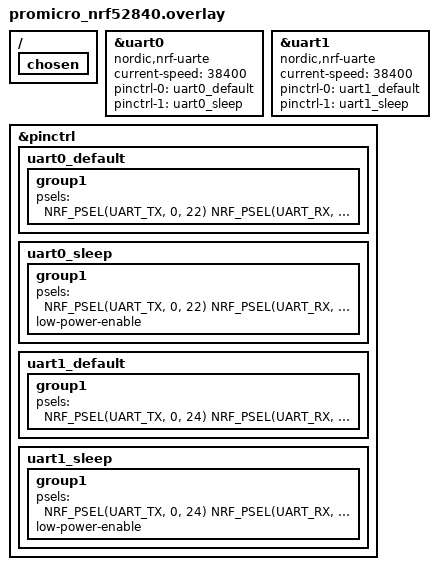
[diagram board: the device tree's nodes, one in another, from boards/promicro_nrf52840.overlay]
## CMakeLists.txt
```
cmake_minimum_required(VERSION 3.20.0)

find_package(Zephyr REQUIRED HINTS $ENV{ZEPHYR_BASE})

project(double_uart_viewer)

target_sources(app PRIVATE src/main.c)
```

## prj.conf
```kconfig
CONFIG_LOG=y
CONFIG_LOG_MODE_IMMEDIATE=y
CONFIG_LOG_BACKEND_UART=n
CONFIG_LOG_BACKEND_RTT=y
CONFIG_USE_SEGGER_RTT=y
CONFIG_RTT_CONSOLE=y
CONFIG_LOG_DEFAULT_LEVEL=4
CONFIG_BUILD_OUTPUT_UF2=y
```

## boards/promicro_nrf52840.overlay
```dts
/ {
    chosen {
    };
};

&uart0 {
    compatible = "nordic,nrf-uarte";
    status = "okay";
    current-speed = <38400>;
    pinctrl-0 = <&uart0_default>;
    pinctrl-1 = <&uart0_sleep>;
    pinctrl-names = "default", "sleep";
};

&uart1 {
    compatible = "nordic,nrf-uarte";
    status = "okay";
    current-speed = <38400>;
    pinctrl-0 = <&uart1_default>;
    pinctrl-1 = <&uart1_sleep>;
    pinctrl-names = "default", "sleep";
};

&pinctrl {
    uart0_default: uart0_default {
        group1 {
            psels = <NRF_PSEL(UART_TX, 0, 22)
                     NRF_PSEL(UART_RX, 0, 20)>;
        };
    };
    uart0_sleep: uart0_sleep {
        group1 {
            psels = <NRF_PSEL(UART_TX, 0, 22)
                     NRF_PSEL(UART_RX, 0, 20)>;
            low-power-enable;
        };
    };
    uart1_default: uart1_default {
        group1 {
            psels = <NRF_PSEL(UART_TX, 0, 24)
                     NRF_PSEL(UART_RX, 1, 0)>;
        };
    };
    uart1_sleep: uart1_sleep {
        group1 {
            psels = <NRF_PSEL(UART_TX, 0, 24)
                     NRF_PSEL(UART_RX, 1, 0)>;
            low-power-enable;
        };
    };
};
```

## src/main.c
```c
#include <zephyr/kernel.h>
#include <zephyr/device.h>
#include <zephyr/drivers/uart.h>
#include <zephyr/drivers/gpio.h>
#include <zephyr/logging/log.h>

LOG_MODULE_REGISTER(main, LOG_LEVEL_DBG);

/* ── UART devices ───────────────────────────────────────────── */
static const struct device *uart0_dev = DEVICE_DT_GET(DT_NODELABEL(uart0));
static const struct device *uart1_dev = DEVICE_DT_GET(DT_NODELABEL(uart1));

/* ── GPIO P0.13 ─────────────────────────────────────────────── */
static const struct device *gpio0_dev = DEVICE_DT_GET(DT_NODELABEL(gpio0));

/* ── Line buffers ───────────────────────────────────────────── */
static char line0[256];
static char line1[256];
static int  idx0;
static int  idx1;

/* ── UART0 callback ─────────────────────────────────────────── */
static void uart0_cb(const struct device *dev, void *user_data)
{
    if (!uart_irq_update(dev) || !uart_irq_rx_ready(dev)) {
        return;
    }

    uint8_t buf[64];
    int len;

    while ((len = uart_fifo_read(dev, buf, sizeof(buf))) > 0) {
        for (int i = 0; i < len; i++) {
            char c = buf[i];
            if (c == '\n' || idx0 >= sizeof(line0) - 1) {
                line0[idx0] = '\0';
                LOG_INF("[UART0] %s", line0);
                idx0 = 0;
            } else if (c != '\r') {
                line0[idx0++] = c;
            }
        }
    }
}

/* ── UART1 callback ─────────────────────────────────────────── */
static void uart1_cb(const struct device *dev, void *user_data)
{
    if (!uart_irq_update(dev) || !uart_irq_rx_ready(dev)) {
        return;
    }

    uint8_t buf[64];
    int len;

    while ((len = uart_fifo_read(dev, buf, sizeof(buf))) > 0) {
        for (int i = 0; i < len; i++) {
            char c = buf[i];
            if (c == '\n' || idx1 >= sizeof(line1) - 1) {
                line1[idx1] = '\0';
                LOG_INF("[UART1] %s", line1);
                idx1 = 0;
            } else if (c != '\r') {
                line1[idx1++] = c;
            }
        }
    }
}

/* ── Main ───────────────────────────────────────────────────── */
int main(void)
{
    /* GPIO P0.13 HIGH */
    if (device_is_ready(gpio0_dev)) {
        gpio_pin_configure(gpio0_dev, 13, GPIO_OUTPUT_ACTIVE);
        gpio_pin_set(gpio0_dev, 13, 1);
        LOG_INF("P0.13 HIGH");
    }

    /* UART0 */
    if (!device_is_ready(uart0_dev)) {
        LOG_ERR("UART0 not ready");
    } else {
        uart_irq_callback_user_data_set(uart0_dev, uart0_cb, NULL);
        uart_irq_rx_enable(uart0_dev);
        LOG_INF("UART0 ready (RX=P0.20 TX=P0.22)");
    }

    /* UART1 */
    if (!device_is_ready(uart1_dev)) {
        LOG_ERR("UART1 not ready");
    } else {
        uart_irq_callback_user_data_set(uart1_dev, uart1_cb, NULL);
        uart_irq_rx_enable(uart1_dev);
        LOG_INF("UART1 ready (RX=P1.00 TX=P0.24)");
    }

    while (1) {
        k_sleep(K_SECONDS(1));
    }

    return 0;
}
```
